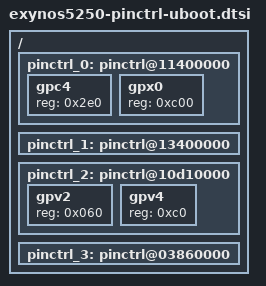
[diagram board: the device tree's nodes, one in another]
/*
 * U-Boot additions to enable a generic Exynos GPIO driver
 *
 * Copyright (c) 2014 Google, Inc
 */

/{
	pinctrl_0: pinctrl@11400000 {
		#address-cells = <1>;
		#size-cells = <0>;
		gpc4: gpc4 {
			reg = <0x2e0>;
		};
		gpx0: gpx0 {
			reg = <0xc00>;
		};
	};

	pinctrl_1: pinctrl@13400000 {
		#address-cells = <1>;
		#size-cells = <0>;
	};

	pinctrl_2: pinctrl@10d10000 {
		#address-cells = <1>;
		#size-cells = <0>;
		gpv2: gpv2 {
			reg = <0x060>;
		};
		gpv4: gpv4 {
			reg = <0xc0>;
		};
	};

	pinctrl_3: pinctrl@03860000 {
		#address-cells = <1>;
		#size-cells = <0>;
	};

};
